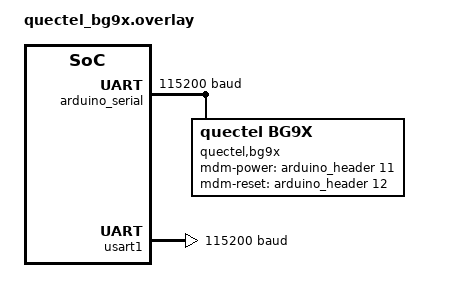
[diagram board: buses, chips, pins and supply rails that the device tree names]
/*
 * Copyright (c) 2019 Foundries.io
 *
 * SPDX-License-Identifier: Apache-2.0
 */

&arduino_serial {
	current-speed = <115200>;
	status = "okay";

	quectel-bg9x {
		label="quectel,bg9x";
		compatible = "quectel,bg9x";
		mdm-power-gpios = <&arduino_header 11 0>; /* D5 */
		mdm-reset-gpios = <&arduino_header 12 0>; /* D6 */
		status = "okay";
	};
};

&usart1{
	current-speed = <115200>;
};

